VERSION ""

NS_ :

BS_:

BU_: LVCU INV BMS AIM

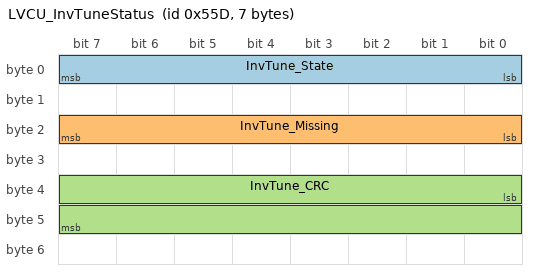
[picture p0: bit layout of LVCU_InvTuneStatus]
BO_ 1373 LVCU_InvTuneStatus: 7 LVCU
 SG_ InvTune_State : 0|8@1+ (1,0) [0|4] "" AIM
 SG_ InvTune_Missing : 16|8@1+ (1,0) [0|255] "" AIM
 SG_ InvTune_CRC : 32|16@1+ (1,0) [0|65535] "" AIM

BO_ 1376 LVCU_InvTuneValue: 4 LVCU
 SG_ InvTune_Addr : 0|16@1+ (1,0) [0|65535] "" AIM
 SG_ InvTune_Value : 16|16@1+ (1,0) [0|65535] "" AIM

CM_ "CT-18EV LVCU inverter EEPROM tune readback frames.";
CM_ BO_ 1373 "Inverter EEPROM readback status. Bytes 1, 3 and 6 (read count, sweeps, parameter count) are left out to save AiM channels";
CM_ SG_ 1373 InvTune_State "0 no inverter, 1 settling, 2 reading, 3 paused (inverter enabled), 4 done";
CM_ SG_ 1373 InvTune_CRC "CRC-16/CCITT-FALSE of all 92 values, little endian, table order. inv_tune_decode.py checks against it";
CM_ BO_ 1376 "One inverter EEPROM parameter per frame, cycling through the table in inv_tune_params.h. Log at 20 Hz or faster and decode with tools/inv_tune_decode.py";
CM_ SG_ 1376 InvTune_Addr "Inverter CAN parameter address";
CM_ SG_ 1376 InvTune_Value "Raw 16 bit value, scaling per parameter. 0x8000 = not read";

BA_DEF_ BO_ "GenMsgCycleTime" INT 0 65535;
BA_DEF_DEF_ "GenMsgCycleTime" 0;
BA_ "GenMsgCycleTime" BO_ 1373 40;
BA_ "GenMsgCycleTime" BO_ 1376 40;

VAL_ 1373 InvTune_State 0 "No inverter" 1 "Settling" 2 "Reading" 3 "Paused" 4 "Done" ;
